# ATSAMD51G18A device description
Architecture: CORTEX-M4; Family: SAMD; Series: SAMD51
Registers are 32-bit, read-write, reset 0x0 unless marked. A register's access mark holds for its fields unless they carry their own. Offsets are from the block's base; [hi:lo] are bit positions; 'fields as' and 'values as' point back to an identical list.

## USER_FUSES — Non-Volatile Fuses
Instances: USER_FUSES 0x00804000 in fuses
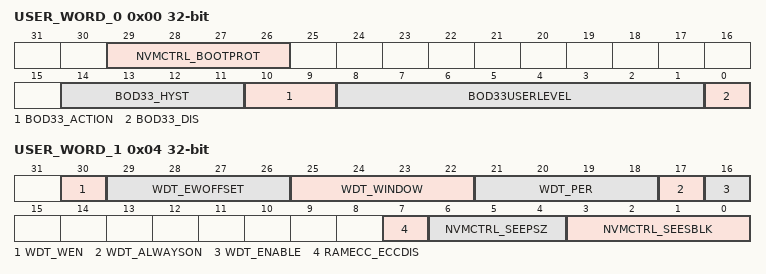
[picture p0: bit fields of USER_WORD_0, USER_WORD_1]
0x00 USER_WORD_0 reset not defined — USER Page Word 0
  [29:26] NVMCTRL_BOOTPROT — Bootloader Size
    15=0 kbytes; 14=8 kbytes; 13=16 kbytes; 12=24 kbytes; 11=32 kbytes; 10=40 kbytes; 9=48 kbytes; 8=56 kbytes; 7=64 kbytes; 6=72 kbytes; 5=80 kbytes; 4=88 kbytes; 3=96 kbytes; 2=104 kbytes; 1=112 kbytes; 0=120 kbytes
  [14:11] BOD33_HYST — BOD33 Hysteresis
  [10:9] BOD33_ACTION
    0=NONE (No action); 1=RESET (The BOD33 generates a reset); 2=INT (The BOD33 generates an interrupt); 3=BKUP (The BOD33 puts the device in backup sleep mode)
  [8:1] BOD33USERLEVEL
  [0] BOD33_DIS — BOD33 Disable
0x04 USER_WORD_1 reset not defined — USER Page Word 1
  [30] WDT_WEN — WDT Window Mode Enable
  [29:26] WDT_EWOFFSET — WDT Early Warning Offset
    0=CYC8 (8 clock cycles); 1=CYC16 (16 clock cycles); 2=CYC32 (32 clock cycles); 3=CYC64 (64 clock cycles); 4=CYC128 (128 clock cycles); 5=CYC256 (256 clock cycles); 6=CYC512 (512 clock cycles); 7=CYC1024 (1024 clock cycles); 8=CYC2048 (2048 clock cycles); 9=CYC4096 (4096 clock cycles); 10=CYC8192 (8192 clock cycles); 11=CYC16384 (16384 clock cycles)
  [25:22] WDT_WINDOW
    values as WDT_EWOFFSET
  [21:18] WDT_PER — WDT Period
    values as WDT_EWOFFSET
  [17] WDT_ALWAYSON
  [16] WDT_ENABLE
  [7] RAMECC_ECCDIS — RAM ECC Disable fuse
  [6:4] NVMCTRL_SEEPSZ — Size Of SmartEEPROM Page
  [3:0] NVMCTRL_SEESBLK — Number Of Physical NVM Blocks Composing a SmartEEPROM Sector
0x08 USER_WORD_2 reset not defined — USER Page Word 2
  [31:0] NVMCTRL_REGION_LOCKS — NVM Region Locks

## OSC32KCTRL — 32kHz Oscillators Control
Instances: OSC32KCTRL 0x40001400
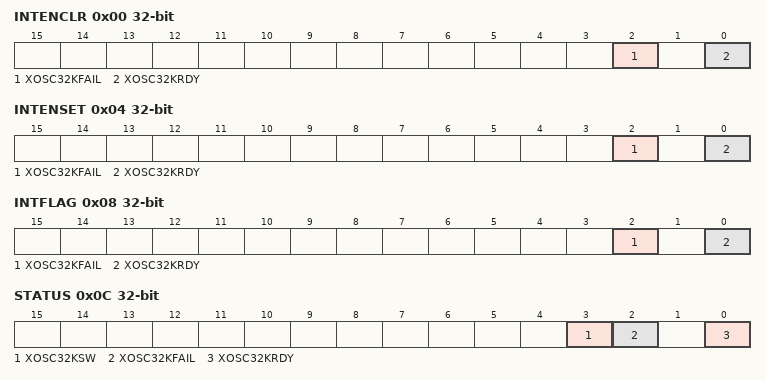
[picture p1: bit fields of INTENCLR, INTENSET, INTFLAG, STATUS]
0x00 INTENCLR (atomic clear) — Interrupt Enable Clear
  [2] XOSC32KFAIL — XOSC32K Clock Failure Detector Interrupt Enable
  [0] XOSC32KRDY — XOSC32K Ready Interrupt Enable
0x04 INTENSET (atomic set) — Interrupt Enable Set
  fields as INTENCLR
0x08 INTFLAG (atomic clear) — Interrupt Flag Status and Clear
  [2] XOSC32KFAIL — XOSC32K Clock Failure Detector
  [0] XOSC32KRDY — XOSC32K Ready
0x0C STATUS ro — Power and Clocks Status
  [3] XOSC32KSW — XOSC32K Clock switch
  [2] XOSC32KFAIL — XOSC32K Clock Failure Detector
  [0] XOSC32KRDY — XOSC32K Ready
0x10 RTCCTRL 8-bit — RTC Clock Selection
  [2:0] RTCSEL
    0=ULP1K (1.024kHz from 32kHz internal ULP oscillator); 1=ULP32K (32.768kHz from 32kHz internal ULP oscillator); 4=XOSC1K (1.024kHz from 32.768kHz internal oscillator); 5=XOSC32K (32.768kHz from 32.768kHz external crystal oscillator)
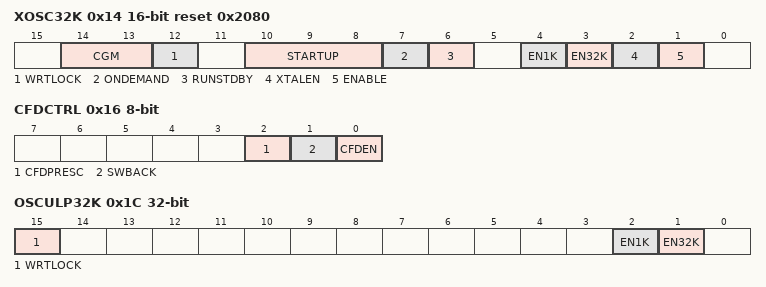
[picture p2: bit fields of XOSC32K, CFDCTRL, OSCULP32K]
0x14 XOSC32K 16-bit reset 0x2080 — 32kHz External Crystal Oscillator (XOSC32K) Control
  [14:13] CGM — Control Gain Mode
    1=XT (Standard mode); 2=HS (High Speed mode)
  [12] WRTLOCK — Write Lock
  [10:8] STARTUP — Oscillator Start-Up Time
    0=CYCLE2048 (62.6 ms); 1=CYCLE4096 (125 ms); 2=CYCLE16384 (500 ms); 3=CYCLE32768 (1000 ms); 4=CYCLE65536 (2000 ms); 5=CYCLE131072 (4000 ms); 6=CYCLE262144 (8000 ms)
  [7] ONDEMAND — On Demand Control
  [6] RUNSTDBY — Run in Standby
  [4] EN1K — 1kHz Output Enable
  [3] EN32K — 32kHz Output Enable
  [2] XTALEN — Crystal Oscillator Enable
  [1] ENABLE — Oscillator Enable
0x16 CFDCTRL 8-bit — Clock Failure Detector Control
  [2] CFDPRESC — Clock Failure Detector Prescaler
  [1] SWBACK — Clock Switch Back
  [0] CFDEN — Clock Failure Detector Enable
0x17 EVCTRL 8-bit — Event Control
  [0] CFDEO — Clock Failure Detector Event Output Enable
0x1C OSCULP32K — 32kHz Ultra Low Power Internal Oscillator (OSCULP32K) Control
  [15] WRTLOCK — Write Lock
  [2] EN1K — Enable Out 1k
  [1] EN32K — Enable Out 32k

## PCC — Parallel Capture Controller
Instances: PCC 0x43002C00
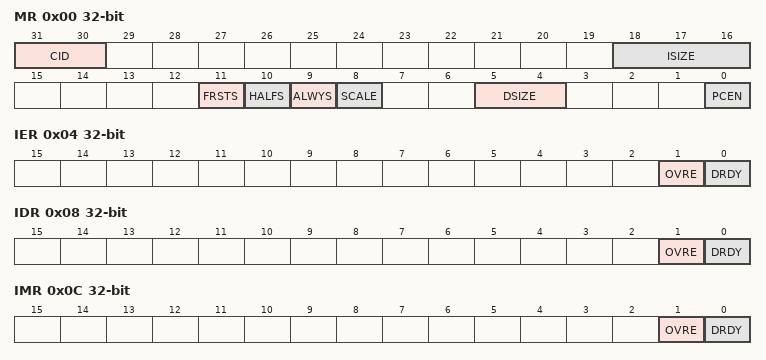
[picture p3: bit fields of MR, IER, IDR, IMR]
0x00 MR — Mode Register
  [31:30] CID — Clear If Disabled
  [18:16] ISIZE — Input Data Size
    0=8BITS (Input data bus size is 8 bits); 1=10BITS (Input data bus size is 10 bits); 2=12BITS (Input data bus size is 12 bits); 3=14BITS (Input data bus size is 14 bits)
  [11] FRSTS — First sample
  [10] HALFS — Half Sampling
  [9] ALWYS — Always Sampling
  [8] SCALE — Scale data
  [5:4] DSIZE — Data size
    0=1DATA (1 data is read in the PCC_RHR); 1=2DATA (2 data is read in the PCC_RHR); 2=4DATA (4 data are read in the PCC_RHR (only for 8 bits data size, ISIZE = 0))
  [0] PCEN — Parallel Capture Enable
0x04 IER wo (atomic set of IMR) — Interrupt Enable Register
  [1] OVRE — Overrun Error Interrupt Enable
  [0] DRDY — Data Ready Interrupt Enable
0x08 IDR wo (atomic clear of IMR) — Interrupt Disable Register
  [1] OVRE — Overrun Error Interrupt Disable
  [0] DRDY — Data Ready Interrupt Disable
0x0C IMR ro — Interrupt Mask Register
  [1] OVRE — Overrun Error Interrupt Mask
  [0] DRDY — Data Ready Interrupt Mask
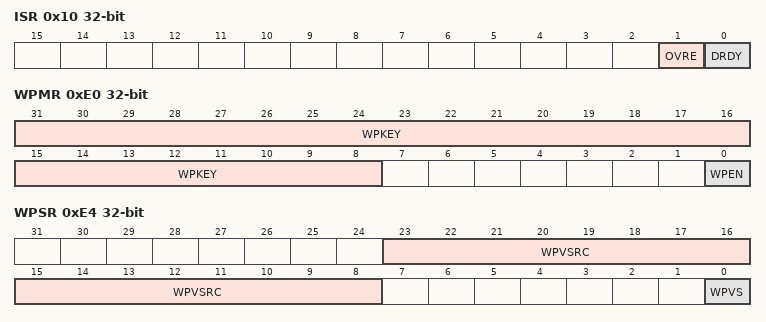
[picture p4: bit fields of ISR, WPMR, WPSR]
0x10 ISR ro — Interrupt Status Register
  [1] OVRE — Overrun Error Interrupt Status
  [0] DRDY — Data Ready Interrupt Status
0x14 RHR ro — Reception Holding Register
  [31:0] RDATA — Reception Data
0xE0 WPMR — Write Protection Mode Register
  [31:8] WPKEY — Write Protection Key
    0x504343=PASSWD (Write Protection Key)
  [0] WPEN — Write Protection Enable
0xE4 WPSR ro — Write Protection Status Register
  [23:8] WPVSRC — Write Protection Violation Status
  [0] WPVS — Write Protection Violation Source
